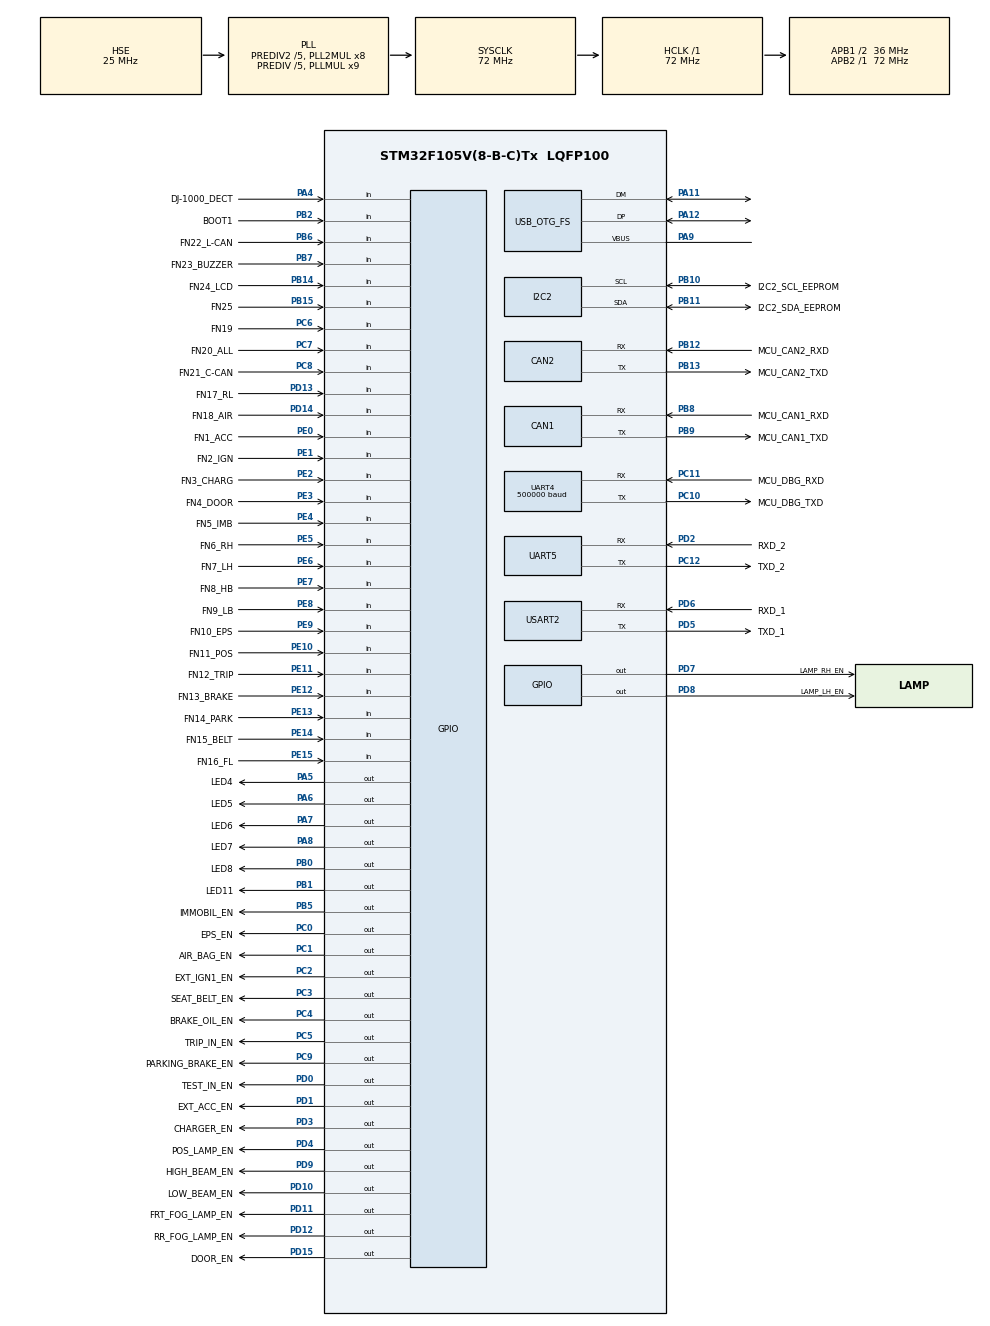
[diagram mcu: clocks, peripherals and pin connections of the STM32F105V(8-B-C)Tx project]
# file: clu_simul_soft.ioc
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CAN1.CalculateTimeBit=1333
CAN1.CalculateTimeQuantum=444.44444444444446
CAN2.CalculateTimeBit=1333
CAN2.CalculateTimeQuantum=444.44444444444446
FREERTOS.Tasks01=CmdTask,24,128,StartCmdTask,Default,NULL,Dynamic,NULL,NULL;GPinTask,24,128,StartGPinTask,Default,NULL,Dynamic,NULL,NULL;GPoutTask,24,128,StartGPoutTask,Default,NULL,Dynamic,NULL,NULL
Mcu.Family=STM32F1
Mcu.Name=STM32F105V(8-B-C)Tx
Mcu.Package=LQFP100
NVIC.CAN1_RX1_IRQn=true\:5\:0\:false\:false\:true\:true\:true\:true
NVIC.CAN2_RX1_IRQn=true\:5\:0\:false\:false\:true\:true\:true\:true
NVIC.OTG_FS_IRQn=true\:5\:0\:false\:false\:true\:true\:false\:true
NVIC.PriorityGroup=NVIC_PRIORITYGROUP_4
NVIC.TIM2_IRQn=true\:5\:0\:false\:false\:true\:true\:true\:true
NVIC.UART4_IRQn=true\:5\:0\:false\:false\:true\:true\:true\:true
OSC_IN.GPIO_Label=MCU_XIN
OSC_IN.Mode=HSE-External-Oscillator
OSC_IN.Signal=RCC_OSC_IN
OSC_OUT.GPIO_Label=MCU_XOUT
OSC_OUT.Mode=HSE-External-Oscillator
OSC_OUT.Signal=RCC_OSC_OUT
PA10.GPIO_Label=OTG_ID
PA10.Signal=USB_OTG_FS_ID
PA11.Mode=Host_Only
PA11.Signal=USB_OTG_FS_DM
PA12.Mode=Host_Only
PA12.Signal=USB_OTG_FS_DP
PA13.GPIO_Label=SWDIO
PA13.Mode=Serial_Wire
PA13.Signal=SYS_JTMS-SWDIO
PA14.GPIO_Label=SWCLK
PA14.Mode=Serial_Wire
PA14.Signal=SYS_JTCK-SWCLK
PA4.GPIO_Label=DJ-1000_DECT
PA4.Signal=GPIO_Input
PA5.GPIO_Label=LED4
PA5.Signal=GPIO_Output
PA6.GPIO_Label=LED5
PA6.Signal=GPIO_Output
PA7.GPIO_Label=LED6
PA7.Signal=GPIO_Output
PA8.GPIO_Label=LED7
PA8.Signal=GPIO_Output
PA9.Mode=Activate_VBUS
PA9.Signal=USB_OTG_FS_VBUS
PB0.GPIO_Label=LED8
PB0.Signal=GPIO_Output
PB1.GPIO_Label=LED11
PB1.Signal=GPIO_Output
PB10.GPIO_Label=I2C2_SCL_EEPROM
PB10.Mode=I2C
PB10.Signal=I2C2_SCL
PB11.GPIO_Label=I2C2_SDA_EEPROM
PB11.Mode=I2C
PB11.Signal=I2C2_SDA
PB12.GPIO_Label=MCU_CAN2_RXD
PB12.Mode=Slave
PB12.Signal=CAN2_RX
PB13.GPIO_Label=MCU_CAN2_TXD
PB13.Mode=Slave
PB13.Signal=CAN2_TX
PB14.GPIO_Label=FN24_LCD
PB14.Signal=GPIO_Input
PB15.GPIO_Label=FN25
PB15.Signal=GPIO_Input
PB2.GPIO_Label=BOOT1
PB2.Signal=GPIO_Input
PB5.GPIO_Label=IMMOBIL_EN
PB5.Signal=GPIO_Output
PB6.GPIO_Label=FN22_L-CAN
PB6.Signal=GPIO_Input
PB7.GPIO_Label=FN23_BUZZER
PB7.Signal=GPIO_Input
PB8.GPIO_Label=MCU_CAN1_RXD
PB8.Mode=Master
PB8.Signal=CAN1_RX
PB9.GPIO_Label=MCU_CAN1_TXD
PB9.Mode=Master
PB9.Signal=CAN1_TX
PC0.GPIO_Label=EPS_EN
PC0.Signal=GPIO_Output
PC1.GPIO_Label=AIR_BAG_EN
PC1.Signal=GPIO_Output
PC10.GPIO_Label=MCU_DBG_TXD
PC10.Mode=Asynchronous
PC10.Signal=UART4_TX
PC11.GPIO_Label=MCU_DBG_RXD
PC11.Mode=Asynchronous
PC11.Signal=UART4_RX
PC12.GPIO_Label=TXD_2
PC12.Mode=Asynchronous
PC12.Signal=UART5_TX
PC14-OSC32_IN.GPIO_Label=MCU_RTC_X1
PC14-OSC32_IN.Signal=RCC_OSC32_IN
PC15-OSC32_OUT.GPIO_Label=MCU_RTC_X2
PC15-OSC32_OUT.Signal=RCC_OSC32_OUT
PC2.GPIO_Label=EXT_IGN1_EN
PC2.Signal=GPIO_Output
PC3.GPIO_Label=SEAT_BELT_EN
PC3.PinState=GPIO_PIN_SET
PC3.Signal=GPIO_Output
PC4.GPIO_Label=BRAKE_OIL_EN
PC4.Signal=GPIO_Output
PC5.GPIO_Label=TRIP_IN_EN
PC5.Signal=GPIO_Output
PC6.GPIO_Label=FN19
PC6.Signal=GPIO_Input
PC7.GPIO_Label=FN20_ALL
PC7.Signal=GPIO_Input
PC8.GPIO_Label=FN21_C-CAN
PC8.Signal=GPIO_Input
PC9.GPIO_Label=PARKING_BRAKE_EN
PC9.Signal=GPIO_Output
PD0.GPIO_Label=TEST_IN_EN
PD0.Signal=GPIO_Output
PD1.GPIO_Label=EXT_ACC_EN
PD1.Signal=GPIO_Output
PD10.GPIO_Label=LOW_BEAM_EN
PD10.Signal=GPIO_Output
PD11.GPIO_Label=FRT_FOG_LAMP_EN
PD11.Signal=GPIO_Output
PD12.GPIO_Label=RR_FOG_LAMP_EN
PD12.Signal=GPIO_Output
PD13.GPIO_Label=FN17_RL
PD13.Signal=GPIO_Input
PD14.GPIO_Label=FN18_AIR
PD14.Signal=GPIO_Input
PD15.GPIO_Label=DOOR_EN
PD15.Signal=GPIO_Output
PD2.GPIO_Label=RXD_2
PD2.Mode=Asynchronous
PD2.Signal=UART5_RX
PD3.GPIO_Label=CHARGER_EN
PD3.Signal=GPIO_Output
PD4.GPIO_Label=POS_LAMP_EN
PD4.Signal=GPIO_Output
PD5.GPIO_Label=TXD_1
PD5.Mode=Asynchronous
PD5.Signal=USART2_TX
PD6.GPIO_Label=RXD_1
PD6.Mode=Asynchronous
PD6.Signal=USART2_RX
PD7.GPIO_Label=LAMP_RH_EN
PD7.Signal=GPIO_Output
PD8.GPIO_Label=LAMP_LH_EN
PD8.Signal=GPIO_Output
PD9.GPIO_Label=HIGH_BEAM_EN
PD9.Signal=GPIO_Output
PE0.GPIO_Label=FN1_ACC
PE0.Signal=GPIO_Input
PE1.GPIO_Label=FN2_IGN
PE1.Signal=GPIO_Input
PE10.GPIO_Label=FN11_POS
PE10.Signal=GPIO_Input
PE11.GPIO_Label=FN12_TRIP
PE11.Signal=GPIO_Input
PE12.GPIO_Label=FN13_BRAKE
PE12.Signal=GPIO_Input
PE13.GPIO_Label=FN14_PARK
PE13.Signal=GPIO_Input
PE14.GPIO_Label=FN15_BELT
PE14.Signal=GPIO_Input
PE15.GPIO_Label=FN16_FL
PE15.Signal=GPIO_Input
PE2.GPIO_Label=FN3_CHARG
PE2.Signal=GPIO_Input
PE3.GPIO_Label=FN4_DOOR
PE3.Signal=GPIO_Input
PE4.GPIO_Label=FN5_IMB
PE4.Signal=GPIO_Input
PE5.GPIO_Label=FN6_RH
PE5.Signal=GPIO_Input
PE6.GPIO_Label=FN7_LH
PE6.Signal=GPIO_Input
PE7.GPIO_Label=FN8_HB
PE7.Signal=GPIO_Input
PE8.GPIO_Label=FN9_LB
PE8.Signal=GPIO_Input
PE9.GPIO_Label=FN10_EPS
PE9.Signal=GPIO_Input
ProjectManager.HeapSize=0x200
ProjectManager.StackSize=0x400
ProjectManager.TargetToolchain=EWARM V8.32
RCC.AHBFreq_Value=72000000
RCC.APB1CLKDivider=RCC_HCLK_DIV2
RCC.APB1Freq_Value=36000000
RCC.APB1TimFreq_Value=72000000
RCC.APB2Freq_Value=72000000
RCC.APB2TimFreq_Value=72000000
RCC.HCLKFreq_Value=72000000
RCC.HSEDivPLL=RCC_HSE_PREDIV_DIV5
RCC.HSE_VALUE=25000000
RCC.PLLMUL=RCC_PLL_MUL9
RCC.PLLSourceVirtual=RCC_PLLSOURCE_HSE
RCC.Prediv1Source=RCC_PREDIV1_SOURCE_PLL2
RCC.Prediv2=RCC_HSE_PREDIV2_DIV5
RCC.SYSCLKFreq_VALUE=72000000
RCC.SYSCLKSource=RCC_SYSCLKSOURCE_PLLCLK
RCC.USBFreq_Value=48000000
TIM2.Period=1000
TIM2.Prescaler=72-1
UART4.BaudRate=500000
UART4.VirtualMode=Asynchronous
UART5.VirtualMode=Asynchronous
USART2.VirtualMode=VM_ASYNC
USB_HOST.USBH_HandleTypeDef=hUsbHostFS
USB_HOST.VirtualModeFS=Msc
USB_OTG_FS.VirtualMode=Host_Only
VP_FATFS_VS_USB.Mode=USB
VP_FREERTOS_VS_CMSIS_V2.Mode=CMSIS_V2
VP_TIM2_VS_ClockSourceINT.Mode=Internal
VP_USB_HOST_VS_USB_HOST_MSC_FS.Mode=MSC_FS
board=custom

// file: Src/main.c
/* USER CODE BEGIN Header */
/**
  ******************************************************************************
  * @file           : main.c
  * @brief          : Main program body
  ******************************************************************************
  * @attention
  *
  * <h2><center>&copy; Copyright (c) 2020 STMicroelectronics.
  * All rights reserved.</center></h2>
  *
  * This software component is licensed by ST under Ultimate Liberty license
  * SLA0044, the "License"; You may not use this file except in compliance with
  * the License. You may obtain a copy of the License at:
  *                             www.st.com/SLA0044
  *
  ******************************************************************************
  * Description :
  *
  *
  * Compiler    : IAR (Ver 8.40.2.22891)
  * CPU         : STM32F105VC
  * Flash       : 256KByte
  * Ram         : 64KByte
  *
  ******************************************************************************
  */
/* USER CODE END Header */

#include "main.h"
#include "cmsis_os.h"
#include "fatfs.h"
#include "usb_host.h"

CAN_HandleTypeDef hcan1;
CAN_HandleTypeDef hcan2;

I2C_HandleTypeDef hi2c2;

TIM_HandleTypeDef htim2;

UART_HandleTypeDef huart4;
UART_HandleTypeDef huart5;
UART_HandleTypeDef huart2;

/* Definitions for CmdTask */
osThreadId_t CmdTaskHandle;
const osThreadAttr_t CmdTask_attributes = {
  .name = "CmdTask",
  .priority = (osPriority_t) osPriorityNormal,
  .stack_size = 128 * 4
};
/* Definitions for GPinTask */
osThreadId_t GPinTaskHandle;
const osThreadAttr_t GPinTask_attributes = {
  .name = "GPinTask",
  .priority = (osPriority_t) osPriorityNormal,
  .stack_size = 128 * 4
};
/* Definitions for GPoutTask */
osThreadId_t GPoutTaskHandle;
const osThreadAttr_t GPoutTask_attributes = {
  .name = "GPoutTask",
  .priority = (osPriority_t) osPriorityNormal,
  .stack_size = 128 * 4
};

void SystemClock_Config(void);
static void MX_GPIO_Init(void);
static void MX_CAN1_Init(void);
static void MX_CAN2_Init(void);
static void MX_I2C2_Init(void);
static void MX_TIM2_Init(void);
static void MX_UART4_Init(void);
static void MX_UART5_Init(void);
static void MX_USART2_UART_Init(void);
void StartCmdTask(void *argument);
void StartGPinTask(void *argument);
void StartGPoutTask(void *argument);

/* USER CODE BEGIN PFP */
#ifdef __GNUC__
/* With GCC, small printf (option LD Linker->Libraries->Small printf
   set to 'Yes') calls __io_putchar() */
#define PUTCHAR_PROTOTYPE int __io_putchar(int ch)
#else
#define PUTCHAR_PROTOTYPE int fputc(int ch, FILE *f)
#endif /* __GNUC__ */
/* USER CODE END PFP */

/* USER CODE BEGIN 0 */
/**
  * @brief  Retargets the C library printf function to the USART.
  * @param  None
  * @retval None
  */
PUTCHAR_PROTOTYPE
{
  /* Place your implementation of fputc here */
  /* e.g. write a character to the USART2 and Loop until the end of transmission */
  HAL_UART_Transmit(&huart4, (uint8_t *)&ch, 1, 0xFFFF);

  return ch;
}

/* USER CODE END 0 */

int main(void)
{

  /* MCU Configuration--------------------------------------------------------*/

  /* Reset of all peripherals, Initializes the Flash interface and the Systick. */
  HAL_Init();

  /* Configure the system clock */
  SystemClock_Config();

  /* Initialize all configured peripherals */
  MX_GPIO_Init();
  MX_CAN1_Init();
  MX_CAN2_Init();
  MX_I2C2_Init();
  MX_TIM2_Init();
  MX_UART4_Init();
  MX_UART5_Init();
  MX_USART2_UART_Init();
  MX_FATFS_Init();
  /* USER CODE BEGIN 2 */
  printf("========================== soft ==========================\r\n");
  printf(" Soft Build Data&Time: %s-%s \r\n", __DATE__, __TIME__);
  printf(" Soft Ver %s \r\n", _FIRMWARE_VERSION_);
  printf(" \"cmd\" shows the dibugging console command. \r\n");
  printf("==========================================================\r\n");

  /* USER CODE END 2 */

  /* Init scheduler */
  osKernelInitialize();

  /* Create the thread(s) */
  /* creation of CmdTask */
  CmdTaskHandle = osThreadNew(StartCmdTask, NULL, &CmdTask_attributes);

  /* creation of GPinTask */
  GPinTaskHandle = osThreadNew(StartGPinTask, NULL, &GPinTask_attributes);

  /* creation of GPoutTask */
  GPoutTaskHandle = osThreadNew(StartGPoutTask, NULL, &GPoutTask_attributes);

  /* Start scheduler */
  osKernelStart();

  /* We should never get here as control is now taken by the scheduler */
  /* Infinite loop */
  while (1)
  {

  }
}

void SystemClock_Config(void)
{
  RCC_OscInitTypeDef RCC_OscInitStruct = {0};
  RCC_ClkInitTypeDef RCC_ClkInitStruct = {0};
  RCC_PeriphCLKInitTypeDef PeriphClkInit = {0};

  /** Initializes the CPU, AHB and APB busses clocks
  */
  RCC_OscInitStruct.OscillatorType = RCC_OSCILLATORTYPE_HSE;
  RCC_OscInitStruct.HSEState = RCC_HSE_ON;
  RCC_OscInitStruct.HSEPredivValue = RCC_HSE_PREDIV_DIV5;
  RCC_OscInitStruct.HSIState = RCC_HSI_ON;
  RCC_OscInitStruct.Prediv1Source = RCC_PREDIV1_SOURCE_PLL2;
  RCC_OscInitStruct.PLL.PLLState = RCC_PLL_ON;
  RCC_OscInitStruct.PLL.PLLSource = RCC_PLLSOURCE_HSE;
  RCC_OscInitStruct.PLL.PLLMUL = RCC_PLL_MUL9;
  RCC_OscInitStruct.PLL2.PLL2State = RCC_PLL2_ON;
  RCC_OscInitStruct.PLL2.PLL2MUL = RCC_PLL2_MUL8;
  RCC_OscInitStruct.PLL2.HSEPrediv2Value = RCC_HSE_PREDIV2_DIV5;
  if (HAL_RCC_OscConfig(&RCC_OscInitStruct) != HAL_OK)
  {
    Error_Handler();
  }
  /** Initializes the CPU, AHB and APB busses clocks
  */
  RCC_ClkInitStruct.ClockType = RCC_CLOCKTYPE_HCLK|RCC_CLOCKTYPE_SYSCLK
                              |RCC_CLOCKTYPE_PCLK1|RCC_CLOCKTYPE_PCLK2;
  RCC_ClkInitStruct.SYSCLKSource = RCC_SYSCLKSOURCE_PLLCLK;
  RCC_ClkInitStruct.AHBCLKDivider = RCC_SYSCLK_DIV1;
  RCC_ClkInitStruct.APB1CLKDivider = RCC_HCLK_DIV2;
  RCC_ClkInitStruct.APB2CLKDivider = RCC_HCLK_DIV1;

  if (HAL_RCC_ClockConfig(&RCC_ClkInitStruct, FLASH_LATENCY_2) != HAL_OK)
  {
    Error_Handler();
  }
  PeriphClkInit.PeriphClockSelection = RCC_PERIPHCLK_USB;
  PeriphClkInit.UsbClockSelection = RCC_USBCLKSOURCE_PLL_DIV3;
  if (HAL_RCCEx_PeriphCLKConfig(&PeriphClkInit) != HAL_OK)
  {
    Error_Handler();
  }
  /** Configure the Systick interrupt time
  */
  __HAL_RCC_PLLI2S_ENABLE();
}

static void MX_CAN1_Init(void)
{

  hcan1.Instance = CAN1;
  hcan1.Init.Prescaler = 16;
  hcan1.Init.Mode = CAN_MODE_NORMAL;
  hcan1.Init.SyncJumpWidth = CAN_SJW_1TQ;
  hcan1.Init.TimeSeg1 = CAN_BS1_1TQ;
  hcan1.Init.TimeSeg2 = CAN_BS2_1TQ;
  hcan1.Init.TimeTriggeredMode = DISABLE;
  hcan1.Init.AutoBusOff = DISABLE;
  hcan1.Init.AutoWakeUp = DISABLE;
  hcan1.Init.AutoRetransmission = DISABLE;
  hcan1.Init.ReceiveFifoLocked = DISABLE;
  hcan1.Init.TransmitFifoPriority = DISABLE;
  if (HAL_CAN_Init(&hcan1) != HAL_OK)
  {
    Error_Handler();
  }

}

static void MX_CAN2_Init(void)
{

  hcan2.Instance = CAN2;
  hcan2.Init.Prescaler = 16;
  hcan2.Init.Mode = CAN_MODE_NORMAL;
  hcan2.Init.SyncJumpWidth = CAN_SJW_1TQ;
  hcan2.Init.TimeSeg1 = CAN_BS1_1TQ;
  hcan2.Init.TimeSeg2 = CAN_BS2_1TQ;
  hcan2.Init.TimeTriggeredMode = DISABLE;
  hcan2.Init.AutoBusOff = DISABLE;
  hcan2.Init.AutoWakeUp = DISABLE;
  hcan2.Init.AutoRetransmission = DISABLE;
  hcan2.Init.ReceiveFifoLocked = DISABLE;
  hcan2.Init.TransmitFifoPriority = DISABLE;
  if (HAL_CAN_Init(&hcan2) != HAL_OK)
  {
    Error_Handler();
  }

}

static void MX_I2C2_Init(void)
{

  hi2c2.Instance = I2C2;
  hi2c2.Init.ClockSpeed = 100000;
  hi2c2.Init.DutyCycle = I2C_DUTYCYCLE_2;
  hi2c2.Init.OwnAddress1 = 0;
  hi2c2.Init.AddressingMode = I2C_ADDRESSINGMODE_7BIT;
  hi2c2.Init.DualAddressMode = I2C_DUALADDRESS_DISABLE;
  hi2c2.Init.OwnAddress2 = 0;
  hi2c2.Init.GeneralCallMode = I2C_GENERALCALL_DISABLE;
  hi2c2.Init.NoStretchMode = I2C_NOSTRETCH_DISABLE;
  if (HAL_I2C_Init(&hi2c2) != HAL_OK)
  {
    Error_Handler();
  }

}

static void MX_TIM2_Init(void)
{

  TIM_ClockConfigTypeDef sClockSourceConfig = {0};
  TIM_MasterConfigTypeDef sMasterConfig = {0};

  htim2.Instance = TIM2;
  htim2.Init.Prescaler = 72-1;
  htim2.Init.CounterMode = TIM_COUNTERMODE_UP;
  htim2.Init.Period = 1000;
  htim2.Init.ClockDivision = TIM_CLOCKDIVISION_DIV1;
  htim2.Init.AutoReloadPreload = TIM_AUTORELOAD_PRELOAD_DISABLE;
  if (HAL_TIM_Base_Init(&htim2) != HAL_OK)
  {
    Error_Handler();
  }
  sClockSourceConfig.ClockSource = TIM_CLOCKSOURCE_INTERNAL;
  if (HAL_TIM_ConfigClockSource(&htim2, &sClockSourceConfig) != HAL_OK)
  {
    Error_Handler();
  }
  sMasterConfig.MasterOutputTrigger = TIM_TRGO_RESET;
  sMasterConfig.MasterSlaveMode = TIM_MASTERSLAVEMODE_DISABLE;
  if (HAL_TIMEx_MasterConfigSynchronization(&htim2, &sMasterConfig) != HAL_OK)
  {
    Error_Handler();
  }

}

static void MX_UART4_Init(void)
{

  huart4.Instance = UART4;
  huart4.Init.BaudRate = 500000;
  huart4.Init.WordLength = UART_WORDLENGTH_8B;
  huart4.Init.StopBits = UART_STOPBITS_1;
  huart4.Init.Parity = UART_PARITY_NONE;
  huart4.Init.Mode = UART_MODE_TX_RX;
  huart4.Init.HwFlowCtl = UART_HWCONTROL_NONE;
  huart4.Init.OverSampling = UART_OVERSAMPLING_16;
  if (HAL_UART_Init(&huart4) != HAL_OK)
  {
    Error_Handler();
  }

}

static void MX_UART5_Init(void)
{

  huart5.Instance = UART5;
  huart5.Init.BaudRate = 115200;
  huart5.Init.WordLength = UART_WORDLENGTH_8B;
  huart5.Init.StopBits = UART_STOPBITS_1;
  huart5.Init.Parity = UART_PARITY_NONE;
  huart5.Init.Mode = UART_MODE_TX_RX;
  huart5.Init.HwFlowCtl = UART_HWCONTROL_NONE;
  huart5.Init.OverSampling = UART_OVERSAMPLING_16;
  if (HAL_UART_Init(&huart5) != HAL_OK)
  {
    Error_Handler();
  }

}

static void MX_USART2_UART_Init(void)
{

  huart2.Instance = USART2;
  huart2.Init.BaudRate = 115200;
  huart2.Init.WordLength = UART_WORDLENGTH_8B;
  huart2.Init.StopBits = UART_STOPBITS_1;
  huart2.Init.Parity = UART_PARITY_NONE;
  huart2.Init.Mode = UART_MODE_TX_RX;
  huart2.Init.HwFlowCtl = UART_HWCONTROL_NONE;
  huart2.Init.OverSampling = UART_OVERSAMPLING_16;
  if (HAL_UART_Init(&huart2) != HAL_OK)
  {
    Error_Handler();
  }

}

static void MX_GPIO_Init(void)
{
  GPIO_InitTypeDef GPIO_InitStruct = {0};

  /* GPIO Ports Clock Enable */
  __HAL_RCC_GPIOE_CLK_ENABLE();
  __HAL_RCC_GPIOC_CLK_ENABLE();
  __HAL_RCC_GPIOA_CLK_ENABLE();
  __HAL_RCC_GPIOB_CLK_ENABLE();
  __HAL_RCC_GPIOD_CLK_ENABLE();

  /*Configure GPIO pin Output Level */
  HAL_GPIO_WritePin(GPIOC, EPS_EN_Pin|AIR_BAG_EN_Pin|EXT_IGN1_EN_Pin|BRAKE_OIL_EN_Pin
                          |TRIP_IN_EN_Pin|PARKING_BRAKE_EN_Pin, GPIO_PIN_RESET);

  /*Configure GPIO pin Output Level */
  HAL_GPIO_WritePin(SEAT_BELT_EN_GPIO_Port, SEAT_BELT_EN_Pin, GPIO_PIN_SET);

  /*Configure GPIO pin Output Level */
  HAL_GPIO_WritePin(GPIOA, LED4_Pin|LED5_Pin|LED6_Pin|LED7_Pin, GPIO_PIN_RESET);

  /*Configure GPIO pin Output Level */
  HAL_GPIO_WritePin(GPIOB, LED8_Pin|LED11_Pin|IMMOBIL_EN_Pin, GPIO_PIN_RESET);

  /*Configure GPIO pin Output Level */
  HAL_GPIO_WritePin(GPIOD, LAMP_LH_EN_Pin|HIGH_BEAM_EN_Pin|LOW_BEAM_EN_Pin|FRT_FOG_LAMP_EN_Pin
                          |RR_FOG_LAMP_EN_Pin|DOOR_EN_Pin|TEST_IN_EN_Pin|EXT_ACC_EN_Pin
                          |CHARGER_EN_Pin|POS_LAMP_EN_Pin|LAMP_RH_EN_Pin, GPIO_PIN_RESET);

  /*Configure GPIO pins : FN3_CHARG_Pin FN4_DOOR_Pin FN5_IMB_Pin FN6_RH_Pin
                           FN7_LH_Pin FN8_HB_Pin FN9_LB_Pin FN10_EPS_Pin
                           FN11_POS_Pin FN12_TRIP_Pin FN13_BRAKE_Pin FN14_PARK_Pin
                           FN15_BELT_Pin FN16_FL_Pin FN1_ACC_Pin FN2_IGN_Pin */
  GPIO_InitStruct.Pin = FN3_CHARG_Pin|FN4_DOOR_Pin|FN5_IMB_Pin|FN6_RH_Pin
                          |FN7_LH_Pin|FN8_HB_Pin|FN9_LB_Pin|FN10_EPS_Pin
                          |FN11_POS_Pin|FN12_TRIP_Pin|FN13_BRAKE_Pin|FN14_PARK_Pin
                          |FN15_BELT_Pin|FN16_FL_Pin|FN1_ACC_Pin|FN2_IGN_Pin;
  GPIO_InitStruct.Mode = GPIO_MODE_INPUT;
  GPIO_InitStruct.Pull = GPIO_NOPULL;
  HAL_GPIO_Init(GPIOE, &GPIO_InitStruct);

  /*Configure GPIO pins : EPS_EN_Pin AIR_BAG_EN_Pin EXT_IGN1_EN_Pin SEAT_BELT_EN_Pin
                           BRAKE_OIL_EN_Pin TRIP_IN_EN_Pin PARKING_BRAKE_EN_Pin */
  GPIO_InitStruct.Pin = EPS_EN_Pin|AIR_BAG_EN_Pin|EXT_IGN1_EN_Pin|SEAT_BELT_EN_Pin
                          |BRAKE_OIL_EN_Pin|TRIP_IN_EN_Pin|PARKING_BRAKE_EN_Pin;
  GPIO_InitStruct.Mode = GPIO_MODE_OUTPUT_PP;
  GPIO_InitStruct.Pull = GPIO_NOPULL;
  GPIO_InitStruct.Speed = GPIO_SPEED_FREQ_LOW;
  HAL_GPIO_Init(GPIOC, &GPIO_InitStruct);

  /*Configure GPIO pin : DJ_1000_DECT_Pin */
  GPIO_InitStruct.Pin = DJ_1000_DECT_Pin;
  GPIO_InitStruct.Mode = GPIO_MODE_INPUT;
  GPIO_InitStruct.Pull = GPIO_NOPULL;
  HAL_GPIO_Init(DJ_1000_DECT_GPIO_Port, &GPIO_InitStruct);

  /*Configure GPIO pins : LED4_Pin LED5_Pin LED6_Pin LED7_Pin */
  GPIO_InitStruct.Pin = LED4_Pin|LED5_Pin|LED6_Pin|LED7_Pin;
  GPIO_InitStruct.Mode = GPIO_MODE_OUTPUT_PP;
  GPIO_InitStruct.Pull = GPIO_NOPULL;
  GPIO_InitStruct.Speed = GPIO_SPEED_FREQ_LOW;
  HAL_GPIO_Init(GPIOA, &GPIO_InitStruct);

  /*Configure GPIO pins : LED8_Pin LED11_Pin IMMOBIL_EN_Pin */
  GPIO_InitStruct.Pin = LED8_Pin|LED11_Pin|IMMOBIL_EN_Pin;
  GPIO_InitStruct.Mode = GPIO_MODE_OUTPUT_PP;
  GPIO_InitStruct.Pull = GPIO_NOPULL;
  GPIO_InitStruct.Speed = GPIO_SPEED_FREQ_LOW;
  HAL_GPIO_Init(GPIOB, &GPIO_InitStruct);

  /*Configure GPIO pins : BOOT1_Pin FN24_LCD_Pin FN25_Pin FN22_L_CAN_Pin
                           FN23_BUZZER_Pin */
  GPIO_InitStruct.Pin = BOOT1_Pin|FN24_LCD_Pin|FN25_Pin|FN22_L_CAN_Pin
                          |FN23_BUZZER_Pin;
  GPIO_InitStruct.Mode = GPIO_MODE_INPUT;
  GPIO_InitStruct.Pull = GPIO_NOPULL;
  HAL_GPIO_Init(GPIOB, &GPIO_InitStruct);

  /*Configure GPIO pins : LAMP_LH_EN_Pin HIGH_BEAM_EN_Pin LOW_BEAM_EN_Pin FRT_FOG_LAMP_EN_Pin
                           RR_FOG_LAMP_EN_Pin DOOR_EN_Pin TEST_IN_EN_Pin EXT_ACC_EN_Pin
                           CHARGER_EN_Pin POS_LAMP_EN_Pin LAMP_RH_EN_Pin */
  GPIO_InitStruct.Pin = LAMP_LH_EN_Pin|HIGH_BEAM_EN_Pin|LOW_BEAM_EN_Pin|FRT_FOG_LAMP_EN_Pin
                          |RR_FOG_LAMP_EN_Pin|DOOR_EN_Pin|TEST_IN_EN_Pin|EXT_ACC_EN_Pin
                          |CHARGER_EN_Pin|POS_LAMP_EN_Pin|LAMP_RH_EN_Pin;
  GPIO_InitStruct.Mode = GPIO_MODE_OUTPUT_PP;
  GPIO_InitStruct.Pull = GPIO_NOPULL;
  GPIO_InitStruct.Speed = GPIO_SPEED_FREQ_LOW;
  HAL_GPIO_Init(GPIOD, &GPIO_InitStruct);

  /*Configure GPIO pins : FN17_RL_Pin FN18_AIR_Pin */
  GPIO_InitStruct.Pin = FN17_RL_Pin|FN18_AIR_Pin;
  GPIO_InitStruct.Mode = GPIO_MODE_INPUT;
  GPIO_InitStruct.Pull = GPIO_NOPULL;
  HAL_GPIO_Init(GPIOD, &GPIO_InitStruct);

  /*Configure GPIO pins : FN19_Pin FN20_ALL_Pin FN21_C_CAN_Pin */
  GPIO_InitStruct.Pin = FN19_Pin|FN20_ALL_Pin|FN21_C_CAN_Pin;
  GPIO_InitStruct.Mode = GPIO_MODE_INPUT;
  GPIO_InitStruct.Pull = GPIO_NOPULL;
  HAL_GPIO_Init(GPIOC, &GPIO_InitStruct);

}

void StartCmdTask(void *argument)
{
  /* init code for USB_HOST */
  MX_USB_HOST_Init();
  for(;;)
  {
    osDelay(1);
  }
}

void StartGPinTask(void *argument)
{
  for(;;)
  {
    osDelay(1);
  }
}

void StartGPoutTask(void *argument)
{
  for(;;)
  {
    osDelay(1);
  }
}

void Error_Handler(void)
{
}

/************************ (C) COPYRIGHT STMicroelectronics *****END OF FILE****/
